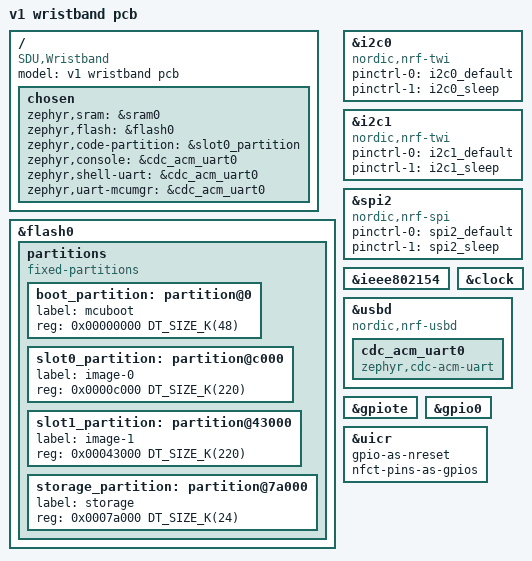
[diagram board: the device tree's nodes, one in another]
/dts-v1/;
#include <nordic/nrf52833_qdaa.dtsi>
#include "Wristband-pinctrl.dtsi"

/ {
	model = "v1 wristband pcb";
	compatible = "SDU,Wristband";

	chosen {
		zephyr,sram = &sram0;
		zephyr,flash = &flash0;
		zephyr,code-partition = &slot0_partition;
		zephyr,console =  &cdc_acm_uart0 ;
		zephyr,shell-uart =  &cdc_acm_uart0 ;
		zephyr,uart-mcumgr = &cdc_acm_uart0;
	};
};

&flash0 {
	partitions {
		compatible = "fixed-partitions";
		#address-cells = <1>;
		#size-cells = <1>;

		boot_partition: partition@0 {
			label = "mcuboot";
			reg = <0x00000000 DT_SIZE_K(48)>;
		};

		slot0_partition: partition@c000 {
			label = "image-0";
			reg = <0x0000c000 DT_SIZE_K(220)>;
		};

		slot1_partition: partition@43000 {
			label = "image-1";
			reg = <0x00043000 DT_SIZE_K(220)>;
		};

		storage_partition: partition@7a000 {
			label = "storage";
			reg = <0x0007a000 DT_SIZE_K(24)>;
		};
	};
};

&i2c0 {
	compatible = "nordic,nrf-twi";
	status = "okay";
	pinctrl-0 = <&i2c0_default>;
	pinctrl-1 = <&i2c0_sleep>;
	pinctrl-names = "default", "sleep";
};

&i2c1 {
	compatible = "nordic,nrf-twi";
	/* Cannot be used together with spi1. */
	status = "okay";
	pinctrl-0 = <&i2c1_default>;
	pinctrl-1 = <&i2c1_sleep>;
	pinctrl-names = "default", "sleep";
};
&spi2 {
	compatible = "nordic,nrf-spi";
	status = "okay";
	pinctrl-0 = <&spi2_default>;
	pinctrl-1 = <&spi2_sleep>;
	pinctrl-names = "default", "sleep";
};

&ieee802154 {
	status = "okay";
};
&clock {
    status = "okay";
};
zephyr_udc0: &usbd {
	compatible = "nordic,nrf-usbd";
	status = "okay";
};

&zephyr_udc0 {
	cdc_acm_uart0: cdc_acm_uart0 {
		compatible = "zephyr,cdc-acm-uart";
	};
};
&gpiote {
	status = "okay";
};

&gpio0 {
	status = "okay";
};
&uicr {
    gpio-as-nreset;
	nfct-pins-as-gpios;
};
